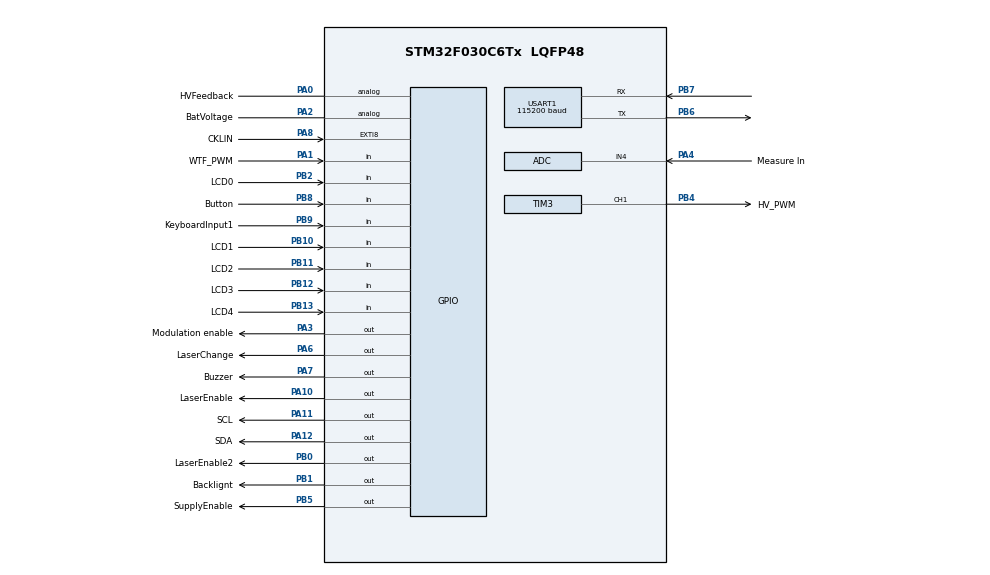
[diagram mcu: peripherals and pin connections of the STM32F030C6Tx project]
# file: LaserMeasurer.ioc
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ADC.ClockPrescaler=ADC_CLOCK_ASYNC_DIV1
ADC.ContinuousConvMode=ENABLE
ADC.DMAContinuousRequests=DISABLE
ADC.DataAlign=ADC_DATAALIGN_LEFT
ADC.DiscontinuousConvMode=DISABLE
ADC.EOCSelection=ADC_EOC_SINGLE_CONV
ADC.EnableAnalogWatchDog=false
ADC.ExternalTrigConv=ADC_SOFTWARE_START
ADC.ExternalTrigConvEdge=ADC_EXTERNALTRIGCONVEDGE_NONE
ADC.LowPowerAutoPowerOff=DISABLE
ADC.LowPowerAutoWait=DISABLE
ADC.Overrun=ADC_OVR_DATA_OVERWRITTEN
ADC.Resolution=ADC_RESOLUTION_12B
ADC.SamplingTime=ADC_SAMPLETIME_1CYCLE_5
ADC.ScanConvMode=ADC_SCAN_DIRECTION_FORWARD
Dma.ADC.0.Direction=DMA_PERIPH_TO_MEMORY
Dma.ADC.0.Instance=DMA1_Channel1
Dma.ADC.0.MemDataAlignment=DMA_MDATAALIGN_BYTE
Dma.ADC.0.MemInc=DMA_MINC_ENABLE
Dma.ADC.0.Mode=DMA_NORMAL
Dma.ADC.0.PeriphDataAlignment=DMA_PDATAALIGN_BYTE
Dma.ADC.0.PeriphInc=DMA_PINC_DISABLE
Dma.ADC.0.Priority=DMA_PRIORITY_HIGH
Dma.Request0=ADC
Mcu.Family=STM32F0
Mcu.Name=STM32F030C6Tx
Mcu.Package=LQFP48
NVIC.DMA1_Channel1_IRQn=true\:0\:0\:false\:false\:true\:false
NVIC.EXTI4_15_IRQn=true\:0\:0\:false\:false\:true\:true
PA0.GPIO_Label=HVFeedback
PA0.Signal=GPIO_Analog
PA1.GPIO_Label=WTF_PWM
PA1.Signal=GPIO_Input
PA10.GPIO_FMA10=__NULL
PA10.GPIO_Label=LaserEnable
PA10.GPIO_Speed=GPIO_SPEED_FREQ_HIGH
PA10.Signal=GPIO_Output
PA11.GPIO_Label=SCL
PA11.GPIO_ModeDefaultOutputPP=GPIO_MODE_OUTPUT_OD
PA11.GPIO_PuPd=GPIO_PULLUP
PA11.GPIO_Speed=GPIO_SPEED_FREQ_HIGH
PA11.PinState=GPIO_PIN_SET
PA11.Signal=GPIO_Output
PA12.GPIO_Label=SDA
PA12.GPIO_ModeDefaultOutputPP=GPIO_MODE_OUTPUT_OD
PA12.GPIO_PuPd=GPIO_PULLUP
PA12.GPIO_Speed=GPIO_SPEED_FREQ_HIGH
PA12.PinState=GPIO_PIN_SET
PA12.Signal=GPIO_Output
PA13.Mode=Serial_Wire
PA13.Signal=SYS_SWDIO
PA14.Mode=Serial_Wire
PA14.Signal=SYS_SWCLK
PA2.GPIO_Label=BatVoltage
PA2.Signal=GPIO_Analog
PA3.GPIO_Label=Modulation enable
PA3.GPIO_Speed=GPIO_SPEED_FREQ_HIGH
PA3.Signal=GPIO_Output
PA4.GPIO_Label=Measure In
PA4.Signal=SharedAnalog_PA4
PA6.GPIO_Label=LaserChange
PA6.GPIO_Speed=GPIO_SPEED_FREQ_HIGH
PA6.Signal=GPIO_Output
PA7.GPIO_Label=Buzzer
PA7.GPIO_Speed=GPIO_SPEED_FREQ_HIGH
PA7.Signal=GPIO_Output
PA8.GPIO_Label=CKLIN
PA8.Signal=GPXTI8
PB0.GPIO_Label=LaserEnable2
PB0.Signal=GPIO_Output
PB1.GPIO_Label=Backlignt
PB1.PinState=GPIO_PIN_SET
PB1.Signal=GPIO_Output
PB10.GPIO_Label=LCD1
PB10.Signal=GPIO_Input
PB11.GPIO_Label=LCD2
PB11.Signal=GPIO_Input
PB12.GPIO_Label=LCD3
PB12.Signal=GPIO_Input
PB13.GPIO_Label=LCD4
PB13.Signal=GPIO_Input
PB2.GPIO_Label=LCD0
PB2.Signal=GPIO_Input
PB4.GPIO_Label=HV_PWM
PB4.GPIO_Speed=GPIO_SPEED_FREQ_HIGH
PB4.Signal=S_TIM3_CH1
PB5.GPIO_Label=SupplyEnable
PB5.PinState=GPIO_PIN_SET
PB5.Signal=GPIO_Output
PB6.GPIO_FM6=__NULL
PB6.Mode=Asynchronous
PB6.Signal=USART1_TX
PB7.Mode=Asynchronous
PB7.Signal=USART1_RX
PB8.GPIO_Label=Button
PB8.Signal=GPIO_Input
PB9.GPIO_Label=KeyboardInput1
PB9.Signal=GPIO_Input
ProjectManager.HeapSize=0x200
ProjectManager.StackSize=0xA00
ProjectManager.TargetToolchain=MDK-ARM V5
RCC.AHBFreq_Value=48000000
RCC.APB1Freq_Value=48000000
RCC.APB1TimFreq_Value=48000000
RCC.HCLKFreq_Value=48000000
RCC.HSE_VALUE=4000000
RCC.PLLMUL=RCC_PLL_MUL12
RCC.RCC_MCOMult_Clock_Source_FROM_PLLMUL=RCC_MCO1SOURCE_PLLCLK_DIV2
RCC.RCC_MCOSource=RCC_MCO1SOURCE_HSI14
RCC.SYSCLKFreq_VALUE=48000000
RCC.SYSCLKSource=RCC_SYSCLKSOURCE_PLLCLK
RCC.TimSys_Div=SYSTICK_CLKSOURCE_HCLK_DIV8
SH.S_TIM3_CH1.0=TIM3_CH1,PWM Generation1 CH1
SH.SharedAnalog_PA4.0=GPIO_Analog
SH.SharedAnalog_PA4.1=ADC_IN4,IN4
TIM3.Channel-PWM\ Generation1\ CH1=TIM_CHANNEL_1
TIM3.Period=599
TIM3.Pulse-PWM\ Generation1\ CH1=120
USART1.BaudRate=115200
USART1.OverrunDisableParam=ADVFEATURE_OVERRUN_DISABLE
USART1.VirtualMode-Asynchronous=VM_ASYNC
board=LaserMeasurer

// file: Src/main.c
/**
  ******************************************************************************
  * @file           : main.c
  * @brief          : Main program body
  ******************************************************************************
  ** This notice applies to any and all portions of this file
  * that are not between comment pairs USER CODE BEGIN and
  * USER CODE END. Other portions of this file, whether
  * inserted by the user or by software development tools
  * are owned by their respective copyright owners.
  *
  * COPYRIGHT(c) 2018 STMicroelectronics
  *
  * Redistribution and use in source and binary forms, with or without modification,
  * are permitted provided that the following conditions are met:
  *   1. Redistributions of source code must retain the above copyright notice,
  *      this list of conditions and the following disclaimer.
  *   2. Redistributions in binary form must reproduce the above copyright notice,
  *      this list of conditions and the following disclaimer in the documentation
  *      and/or other materials provided with the distribution.
  *   3. Neither the name of STMicroelectronics nor the names of its contributors
  *      may be used to endorse or promote products derived from this software
  *      without specific prior written permission.
  *
  * THIS SOFTWARE IS PROVIDED BY THE COPYRIGHT HOLDERS AND CONTRIBUTORS "AS IS"
  * AND ANY EXPRESS OR IMPLIED WARRANTIES, INCLUDING, BUT NOT LIMITED TO, THE
  * IMPLIED WARRANTIES OF MERCHANTABILITY AND FITNESS FOR A PARTICULAR PURPOSE ARE
  * DISCLAIMED. IN NO EVENT SHALL THE COPYRIGHT HOLDER OR CONTRIBUTORS BE LIABLE
  * FOR ANY DIRECT, INDIRECT, INCIDENTAL, SPECIAL, EXEMPLARY, OR CONSEQUENTIAL
  * DAMAGES (INCLUDING, BUT NOT LIMITED TO, PROCUREMENT OF SUBSTITUTE GOODS OR
  * SERVICES; LOSS OF USE, DATA, OR PROFITS; OR BUSINESS INTERRUPTION) HOWEVER
  * CAUSED AND ON ANY THEORY OF LIABILITY, WHETHER IN CONTRACT, STRICT LIABILITY,
  * OR TORT (INCLUDING NEGLIGENCE OR OTHERWISE) ARISING IN ANY WAY OUT OF THE USE
  * OF THIS SOFTWARE, EVEN IF ADVISED OF THE POSSIBILITY OF SUCH DAMAGE.
  *
  ******************************************************************************
  */
#include "main.h"

/* USER CODE BEGIN Includes */

#include "platform.h"

/* USER CODE END Includes */

/* USER CODE BEGIN PV */
/* Private variables ---------------------------------------------------------*/

/* USER CODE END PV */

static void LL_Init(void);
void SystemClock_Config(void);
static void MX_GPIO_Init(void);
static void MX_DMA_Init(void);
static void MX_USART1_UART_Init(void);
static void MX_ADC_Init(void);
static void MX_TIM3_Init(void);

/* USER CODE BEGIN PFP */
/* Private function prototypes -----------------------------------------------*/

/* USER CODE END PFP */

int main(void)
{

  /* MCU Configuration----------------------------------------------------------*/

  /* Reset of all peripherals, Initializes the Flash interface and the Systick. */
  LL_Init();

  /* Configure the system clock */
  SystemClock_Config();

  /* Initialize all configured peripherals */
  MX_GPIO_Init();
  MX_DMA_Init();
  MX_USART1_UART_Init();
  MX_ADC_Init();
  MX_TIM3_Init();
  /* USER CODE BEGIN 2 */

  SysTick_Config(6000000);
  LL_SYSTICK_SetClkSource(LL_SYSTICK_CLKSOURCE_HCLK_DIV8);
  LL_ADC_Enable(ADC1);
  LL_TIM_EnableCounter(TIM3);
  LL_TIM_CC_EnableChannel(TIM3, LL_TIM_CHANNEL_CH1);
  PlatformInit();

  /* USER CODE END 2 */

  /* Infinite loop */
  /* USER CODE BEGIN WHILE */
  while (1)
  {
	PlatformLoop();
  /* USER CODE END WHILE */

  }

}

static void LL_Init(void)
{

  LL_APB1_GRP2_EnableClock(LL_APB1_GRP2_PERIPH_SYSCFG);

  /* System interrupt init*/
  /* SVC_IRQn interrupt configuration */
  NVIC_SetPriority(SVC_IRQn, 0);
  /* PendSV_IRQn interrupt configuration */
  NVIC_SetPriority(PendSV_IRQn, 0);
  /* SysTick_IRQn interrupt configuration */
  NVIC_SetPriority(SysTick_IRQn, 0);

}

void SystemClock_Config(void)
{

  LL_FLASH_SetLatency(LL_FLASH_LATENCY_1);

  if(LL_FLASH_GetLatency() != LL_FLASH_LATENCY_1)
  {
  Error_Handler();
  }
  LL_RCC_HSI_Enable();

   /* Wait till HSI is ready */
  while(LL_RCC_HSI_IsReady() != 1)
  {

  }
  LL_RCC_HSI_SetCalibTrimming(16);

  LL_RCC_HSI14_Enable();

   /* Wait till HSI14 is ready */
  while(LL_RCC_HSI14_IsReady() != 1)
  {

  }
  LL_RCC_HSI14_SetCalibTrimming(16);

  LL_RCC_PLL_ConfigDomain_SYS(LL_RCC_PLLSOURCE_HSI_DIV_2, LL_RCC_PLL_MUL_12);

  LL_RCC_PLL_Enable();

   /* Wait till PLL is ready */
  while(LL_RCC_PLL_IsReady() != 1)
  {

  }
  LL_RCC_SetAHBPrescaler(LL_RCC_SYSCLK_DIV_1);

  LL_RCC_SetAPB1Prescaler(LL_RCC_APB1_DIV_1);

  LL_RCC_SetSysClkSource(LL_RCC_SYS_CLKSOURCE_PLL);

   /* Wait till System clock is ready */
  while(LL_RCC_GetSysClkSource() != LL_RCC_SYS_CLKSOURCE_STATUS_PLL)
  {

  }
  LL_Init1msTick(6000000);

  LL_SYSTICK_SetClkSource(LL_SYSTICK_CLKSOURCE_HCLK_DIV8);

  LL_SetSystemCoreClock(48000000);

  LL_RCC_HSI14_EnableADCControl();

  LL_RCC_SetUSARTClockSource(LL_RCC_USART1_CLKSOURCE_PCLK1);

  /* SysTick_IRQn interrupt configuration */
  NVIC_SetPriority(SysTick_IRQn, 0);
}

/* ADC init function */
static void MX_ADC_Init(void)
{

  LL_ADC_InitTypeDef ADC_InitStruct;
  LL_ADC_REG_InitTypeDef ADC_REG_InitStruct;

  LL_GPIO_InitTypeDef GPIO_InitStruct;

  /* Peripheral clock enable */
  LL_APB1_GRP2_EnableClock(LL_APB1_GRP2_PERIPH_ADC1);

  /**ADC GPIO Configuration
  PA4   ------> ADC_IN4
  */
  GPIO_InitStruct.Pin = Measure_In_Pin;
  GPIO_InitStruct.Mode = LL_GPIO_MODE_ANALOG;
  GPIO_InitStruct.Pull = LL_GPIO_PULL_NO;
  LL_GPIO_Init(Measure_In_GPIO_Port, &GPIO_InitStruct);

  /* ADC DMA Init */

  /* ADC Init */
  LL_DMA_SetDataTransferDirection(DMA1, LL_DMA_CHANNEL_1, LL_DMA_DIRECTION_PERIPH_TO_MEMORY);

  LL_DMA_SetChannelPriorityLevel(DMA1, LL_DMA_CHANNEL_1, LL_DMA_PRIORITY_HIGH);

  LL_DMA_SetMode(DMA1, LL_DMA_CHANNEL_1, LL_DMA_MODE_NORMAL);

  LL_DMA_SetPeriphIncMode(DMA1, LL_DMA_CHANNEL_1, LL_DMA_PERIPH_NOINCREMENT);

  LL_DMA_SetMemoryIncMode(DMA1, LL_DMA_CHANNEL_1, LL_DMA_MEMORY_INCREMENT);

  LL_DMA_SetPeriphSize(DMA1, LL_DMA_CHANNEL_1, LL_DMA_PDATAALIGN_BYTE);

  LL_DMA_SetMemorySize(DMA1, LL_DMA_CHANNEL_1, LL_DMA_MDATAALIGN_BYTE);

    /**Configure Regular Channel
    */
  LL_ADC_REG_SetSequencerChannels(ADC1, LL_ADC_CHANNEL_4);

    /**Configure the global features of the ADC (Clock, Resolution, Data Alignment and number of conversion)
    */
  ADC_InitStruct.Clock = LL_ADC_CLOCK_ASYNC;
  ADC_InitStruct.Resolution = LL_ADC_RESOLUTION_12B;
  ADC_InitStruct.DataAlignment = LL_ADC_DATA_ALIGN_LEFT;
  ADC_InitStruct.LowPowerMode = LL_ADC_LP_MODE_NONE;
  LL_ADC_Init(ADC1, &ADC_InitStruct);

  ADC_REG_InitStruct.TriggerSource = LL_ADC_REG_TRIG_SOFTWARE;
  ADC_REG_InitStruct.SequencerDiscont = LL_ADC_REG_SEQ_DISCONT_DISABLE;
  ADC_REG_InitStruct.ContinuousMode = LL_ADC_REG_CONV_CONTINUOUS;
  ADC_REG_InitStruct.DMATransfer = LL_ADC_REG_DMA_TRANSFER_LIMITED;
  ADC_REG_InitStruct.Overrun = LL_ADC_REG_OVR_DATA_OVERWRITTEN;
  LL_ADC_REG_Init(ADC1, &ADC_REG_InitStruct);

  LL_ADC_REG_SetSequencerScanDirection(ADC1, LL_ADC_REG_SEQ_SCAN_DIR_FORWARD);

  LL_ADC_SetSamplingTimeCommonChannels(ADC1, LL_ADC_SAMPLINGTIME_1CYCLE_5);

  LL_ADC_EnableIT_EOC(ADC1);

  LL_ADC_DisableIT_EOS(ADC1);

}

/* TIM3 init function */
static void MX_TIM3_Init(void)
{

  LL_TIM_InitTypeDef TIM_InitStruct;
  LL_TIM_OC_InitTypeDef TIM_OC_InitStruct;

  LL_GPIO_InitTypeDef GPIO_InitStruct;

  /* Peripheral clock enable */
  LL_APB1_GRP1_EnableClock(LL_APB1_GRP1_PERIPH_TIM3);

  TIM_InitStruct.Prescaler = 0;
  TIM_InitStruct.CounterMode = LL_TIM_COUNTERMODE_UP;
  TIM_InitStruct.Autoreload = 599;
  TIM_InitStruct.ClockDivision = LL_TIM_CLOCKDIVISION_DIV1;
  LL_TIM_Init(TIM3, &TIM_InitStruct);

  LL_TIM_DisableARRPreload(TIM3);

  LL_TIM_OC_EnablePreload(TIM3, LL_TIM_CHANNEL_CH1);

  TIM_OC_InitStruct.OCMode = LL_TIM_OCMODE_PWM1;
  TIM_OC_InitStruct.OCState = LL_TIM_OCSTATE_DISABLE;
  TIM_OC_InitStruct.OCNState = LL_TIM_OCSTATE_DISABLE;
  TIM_OC_InitStruct.CompareValue = 120;
  TIM_OC_InitStruct.OCPolarity = LL_TIM_OCPOLARITY_HIGH;
  LL_TIM_OC_Init(TIM3, LL_TIM_CHANNEL_CH1, &TIM_OC_InitStruct);

  LL_TIM_OC_DisableFast(TIM3, LL_TIM_CHANNEL_CH1);

  LL_TIM_SetTriggerOutput(TIM3, LL_TIM_TRGO_RESET);

  LL_TIM_DisableMasterSlaveMode(TIM3);

  /**TIM3 GPIO Configuration
  PB4   ------> TIM3_CH1
  */
  GPIO_InitStruct.Pin = HV_PWM_Pin;
  GPIO_InitStruct.Mode = LL_GPIO_MODE_ALTERNATE;
  GPIO_InitStruct.Speed = LL_GPIO_SPEED_FREQ_HIGH;
  GPIO_InitStruct.OutputType = LL_GPIO_OUTPUT_PUSHPULL;
  GPIO_InitStruct.Pull = LL_GPIO_PULL_NO;
  GPIO_InitStruct.Alternate = LL_GPIO_AF_1;
  LL_GPIO_Init(HV_PWM_GPIO_Port, &GPIO_InitStruct);

}

/* USART1 init function */
static void MX_USART1_UART_Init(void)
{

  LL_USART_InitTypeDef USART_InitStruct;

  LL_GPIO_InitTypeDef GPIO_InitStruct;

  /* Peripheral clock enable */
  LL_APB1_GRP2_EnableClock(LL_APB1_GRP2_PERIPH_USART1);

  /**USART1 GPIO Configuration
  PB6   ------> USART1_TX
  PB7   ------> USART1_RX
  */
  GPIO_InitStruct.Pin = LL_GPIO_PIN_6;
  GPIO_InitStruct.Mode = LL_GPIO_MODE_ALTERNATE;
  GPIO_InitStruct.Speed = LL_GPIO_SPEED_FREQ_HIGH;
  GPIO_InitStruct.OutputType = LL_GPIO_OUTPUT_PUSHPULL;
  GPIO_InitStruct.Pull = LL_GPIO_PULL_NO;
  GPIO_InitStruct.Alternate = LL_GPIO_AF_0;
  LL_GPIO_Init(GPIOB, &GPIO_InitStruct);

  GPIO_InitStruct.Pin = LL_GPIO_PIN_7;
  GPIO_InitStruct.Mode = LL_GPIO_MODE_ALTERNATE;
  GPIO_InitStruct.Speed = LL_GPIO_SPEED_FREQ_HIGH;
  GPIO_InitStruct.OutputType = LL_GPIO_OUTPUT_PUSHPULL;
  GPIO_InitStruct.Pull = LL_GPIO_PULL_NO;
  GPIO_InitStruct.Alternate = LL_GPIO_AF_0;
  LL_GPIO_Init(GPIOB, &GPIO_InitStruct);

  USART_InitStruct.BaudRate = 115200;
  USART_InitStruct.DataWidth = LL_USART_DATAWIDTH_8B;
  USART_InitStruct.StopBits = LL_USART_STOPBITS_1;
  USART_InitStruct.Parity = LL_USART_PARITY_NONE;
  USART_InitStruct.TransferDirection = LL_USART_DIRECTION_TX_RX;
  USART_InitStruct.HardwareFlowControl = LL_USART_HWCONTROL_NONE;
  USART_InitStruct.OverSampling = LL_USART_OVERSAMPLING_16;
  LL_USART_Init(USART1, &USART_InitStruct);

  LL_USART_DisableIT_CTS(USART1);

  LL_USART_EnableOverrunDetect(USART1);

  LL_USART_ConfigAsyncMode(USART1);

  LL_USART_Enable(USART1);

}

static void MX_DMA_Init(void)
{
  /* Init with LL driver */
  /* DMA controller clock enable */
  LL_AHB1_GRP1_EnableClock(LL_AHB1_GRP1_PERIPH_DMA1);

  /* DMA interrupt init */
  /* DMA1_Channel1_IRQn interrupt configuration */
  NVIC_SetPriority(DMA1_Channel1_IRQn, 0);
  NVIC_EnableIRQ(DMA1_Channel1_IRQn);

}

/** Configure pins as
        * Analog
        * Input
        * Output
        * EVENT_OUT
        * EXTI
     PA4   ------> SharedAnalog_PA4
*/
static void MX_GPIO_Init(void)
{

  LL_EXTI_InitTypeDef EXTI_InitStruct;
  LL_GPIO_InitTypeDef GPIO_InitStruct;

  /* GPIO Ports Clock Enable */
  LL_AHB1_GRP1_EnableClock(LL_AHB1_GRP1_PERIPH_GPIOA);
  LL_AHB1_GRP1_EnableClock(LL_AHB1_GRP1_PERIPH_GPIOB);

  /**/
  LL_GPIO_ResetOutputPin(Modulation_enable_GPIO_Port, Modulation_enable_Pin);

  /**/
  LL_GPIO_ResetOutputPin(LaserChange_GPIO_Port, LaserChange_Pin);

  /**/
  LL_GPIO_ResetOutputPin(Buzzer_GPIO_Port, Buzzer_Pin);

  /**/
  LL_GPIO_ResetOutputPin(LaserEnable2_GPIO_Port, LaserEnable2_Pin);

  /**/
  LL_GPIO_ResetOutputPin(LaserEnable_GPIO_Port, LaserEnable_Pin);

  /**/
  LL_GPIO_SetOutputPin(Backlignt_GPIO_Port, Backlignt_Pin);

  /**/
  LL_GPIO_SetOutputPin(SCL_GPIO_Port, SCL_Pin);

  /**/
  LL_GPIO_SetOutputPin(SDA_GPIO_Port, SDA_Pin);

  /**/
  LL_GPIO_SetOutputPin(SupplyEnable_GPIO_Port, SupplyEnable_Pin);

  /**/
  GPIO_InitStruct.Pin = HVFeedback_Pin;
  GPIO_InitStruct.Mode = LL_GPIO_MODE_ANALOG;
  GPIO_InitStruct.Pull = LL_GPIO_PULL_NO;
  LL_GPIO_Init(HVFeedback_GPIO_Port, &GPIO_InitStruct);

  /**/
  GPIO_InitStruct.Pin = WTF_PWM_Pin;
  GPIO_InitStruct.Mode = LL_GPIO_MODE_INPUT;
  GPIO_InitStruct.Pull = LL_GPIO_PULL_NO;
  LL_GPIO_Init(WTF_PWM_GPIO_Port, &GPIO_InitStruct);

  /**/
  GPIO_InitStruct.Pin = BatVoltage_Pin;
  GPIO_InitStruct.Mode = LL_GPIO_MODE_ANALOG;
  GPIO_InitStruct.Pull = LL_GPIO_PULL_NO;
  LL_GPIO_Init(BatVoltage_GPIO_Port, &GPIO_InitStruct);

  /**/
  GPIO_InitStruct.Pin = Modulation_enable_Pin;
  GPIO_InitStruct.Mode = LL_GPIO_MODE_OUTPUT;
  GPIO_InitStruct.Speed = LL_GPIO_SPEED_FREQ_HIGH;
  GPIO_InitStruct.OutputType = LL_GPIO_OUTPUT_PUSHPULL;
  GPIO_InitStruct.Pull = LL_GPIO_PULL_NO;
  LL_GPIO_Init(Modulation_enable_GPIO_Port, &GPIO_InitStruct);

  /**/
  GPIO_InitStruct.Pin = Measure_In_Pin;
  GPIO_InitStruct.Mode = LL_GPIO_MODE_ANALOG;
  GPIO_InitStruct.Pull = LL_GPIO_PULL_NO;
  LL_GPIO_Init(Measure_In_GPIO_Port, &GPIO_InitStruct);

  /**/
  GPIO_InitStruct.Pin = LaserChange_Pin;
  GPIO_InitStruct.Mode = LL_GPIO_MODE_OUTPUT;
  GPIO_InitStruct.Speed = LL_GPIO_SPEED_FREQ_HIGH;
  GPIO_InitStruct.OutputType = LL_GPIO_OUTPUT_PUSHPULL;
  GPIO_InitStruct.Pull = LL_GPIO_PULL_NO;
  LL_GPIO_Init(LaserChange_GPIO_Port, &GPIO_InitStruct);

  /**/
  GPIO_InitStruct.Pin = Buzzer_Pin;
  GPIO_InitStruct.Mode = LL_GPIO_MODE_OUTPUT;
  GPIO_InitStruct.Speed = LL_GPIO_SPEED_FREQ_HIGH;
  GPIO_InitStruct.OutputType = LL_GPIO_OUTPUT_PUSHPULL;
  GPIO_InitStruct.Pull = LL_GPIO_PULL_NO;
  LL_GPIO_Init(Buzzer_GPIO_Port, &GPIO_InitStruct);

  /**/
  GPIO_InitStruct.Pin = LaserEnable2_Pin;
  GPIO_InitStruct.Mode = LL_GPIO_MODE_OUTPUT;
  GPIO_InitStruct.Speed = LL_GPIO_SPEED_FREQ_LOW;
  GPIO_InitStruct.OutputType = LL_GPIO_OUTPUT_PUSHPULL;
  GPIO_InitStruct.Pull = LL_GPIO_PULL_NO;
  LL_GPIO_Init(LaserEnable2_GPIO_Port, &GPIO_InitStruct);

  /**/
  GPIO_InitStruct.Pin = Backlignt_Pin;
  GPIO_InitStruct.Mode = LL_GPIO_MODE_OUTPUT;
  GPIO_InitStruct.Speed = LL_GPIO_SPEED_FREQ_LOW;
  GPIO_InitStruct.OutputType = LL_GPIO_OUTPUT_PUSHPULL;
  GPIO_InitStruct.Pull = LL_GPIO_PULL_NO;
  LL_GPIO_Init(Backlignt_GPIO_Port, &GPIO_InitStruct);

  /**/
  GPIO_InitStruct.Pin = LCD0_Pin;
  GPIO_InitStruct.Mode = LL_GPIO_MODE_INPUT;
  GPIO_InitStruct.Pull = LL_GPIO_PULL_NO;
  LL_GPIO_Init(LCD0_GPIO_Port, &GPIO_InitStruct);

  /**/
  GPIO_InitStruct.Pin = LCD1_Pin;
  GPIO_InitStruct.Mode = LL_GPIO_MODE_INPUT;
  GPIO_InitStruct.Pull = LL_GPIO_PULL_NO;
  LL_GPIO_Init(LCD1_GPIO_Port, &GPIO_InitStruct);

  /**/
  GPIO_InitStruct.Pin = LCD2_Pin;
  GPIO_InitStruct.Mode = LL_GPIO_MODE_INPUT;
  GPIO_InitStruct.Pull = LL_GPIO_PULL_NO;
  LL_GPIO_Init(LCD2_GPIO_Port, &GPIO_InitStruct);

  /**/
  GPIO_InitStruct.Pin = LCD3_Pin;
  GPIO_InitStruct.Mode = LL_GPIO_MODE_INPUT;
  GPIO_InitStruct.Pull = LL_GPIO_PULL_NO;
  LL_GPIO_Init(LCD3_GPIO_Port, &GPIO_InitStruct);

  /**/
  GPIO_InitStruct.Pin = LCD4_Pin;
  GPIO_InitStruct.Mode = LL_GPIO_MODE_INPUT;
  GPIO_InitStruct.Pull = LL_GPIO_PULL_NO;
  LL_GPIO_Init(LCD4_GPIO_Port, &GPIO_InitStruct);

  /**/
  GPIO_InitStruct.Pin = LaserEnable_Pin;
  GPIO_InitStruct.Mode = LL_GPIO_MODE_OUTPUT;
  GPIO_InitStruct.Speed = LL_GPIO_SPEED_FREQ_HIGH;
  GPIO_InitStruct.OutputType = LL_GPIO_OUTPUT_PUSHPULL;
  GPIO_InitStruct.Pull = LL_GPIO_PULL_NO;
  LL_GPIO_Init(LaserEnable_GPIO_Port, &GPIO_InitStruct);

  /**/
  GPIO_InitStruct.Pin = SCL_Pin;
  GPIO_InitStruct.Mode = LL_GPIO_MODE_OUTPUT;
  GPIO_InitStruct.Speed = LL_GPIO_SPEED_FREQ_HIGH;
  GPIO_InitStruct.OutputType = LL_GPIO_OUTPUT_OPENDRAIN;
  GPIO_InitStruct.Pull = LL_GPIO_PULL_UP;
  LL_GPIO_Init(SCL_GPIO_Port, &GPIO_InitStruct);

  /**/
  GPIO_InitStruct.Pin = SDA_Pin;
  GPIO_InitStruct.Mode = LL_GPIO_MODE_OUTPUT;
  GPIO_InitStruct.Speed = LL_GPIO_SPEED_FREQ_HIGH;
  GPIO_InitStruct.OutputType = LL_GPIO_OUTPUT_OPENDRAIN;
  GPIO_InitStruct.Pull = LL_GPIO_PULL_UP;
  LL_GPIO_Init(SDA_GPIO_Port, &GPIO_InitStruct);

  /**/
  GPIO_InitStruct.Pin = SupplyEnable_Pin;
  GPIO_InitStruct.Mode = LL_GPIO_MODE_OUTPUT;
  GPIO_InitStruct.Speed = LL_GPIO_SPEED_FREQ_LOW;
  GPIO_InitStruct.OutputType = LL_GPIO_OUTPUT_PUSHPULL;
  GPIO_InitStruct.Pull = LL_GPIO_PULL_NO;
  LL_GPIO_Init(SupplyEnable_GPIO_Port, &GPIO_InitStruct);

  /**/
  GPIO_InitStruct.Pin = Button_Pin;
  GPIO_InitStruct.Mode = LL_GPIO_MODE_INPUT;
  GPIO_InitStruct.Pull = LL_GPIO_PULL_NO;
  LL_GPIO_Init(Button_GPIO_Port, &GPIO_InitStruct);

  /**/
  GPIO_InitStruct.Pin = KeyboardInput1_Pin;
  GPIO_InitStruct.Mode = LL_GPIO_MODE_INPUT;
  GPIO_InitStruct.Pull = LL_GPIO_PULL_NO;
  LL_GPIO_Init(KeyboardInput1_GPIO_Port, &GPIO_InitStruct);

  /**/
  LL_SYSCFG_SetEXTISource(LL_SYSCFG_EXTI_PORTA, LL_SYSCFG_EXTI_LINE8);

  /**/
  LL_GPIO_SetPinPull(CKLIN_GPIO_Port, CKLIN_Pin, LL_GPIO_PULL_NO);

  /**/
  LL_GPIO_SetPinMode(CKLIN_GPIO_Port, CKLIN_Pin, LL_GPIO_MODE_INPUT);

  /**/
  EXTI_InitStruct.Line_0_31 = LL_EXTI_LINE_8;
  EXTI_InitStruct.LineCommand = ENABLE;
  EXTI_InitStruct.Mode = LL_EXTI_MODE_IT;
  EXTI_InitStruct.Trigger = LL_EXTI_TRIGGER_RISING;
  LL_EXTI_Init(&EXTI_InitStruct);

  /* EXTI interrupt init*/
  NVIC_SetPriority(EXTI4_15_IRQn, 0);
  NVIC_EnableIRQ(EXTI4_15_IRQn);

}

void _Error_Handler(char *file, int line)
{
  while(1)
  {
  }
}

/************************ (C) COPYRIGHT STMicroelectronics *****END OF FILE****/
